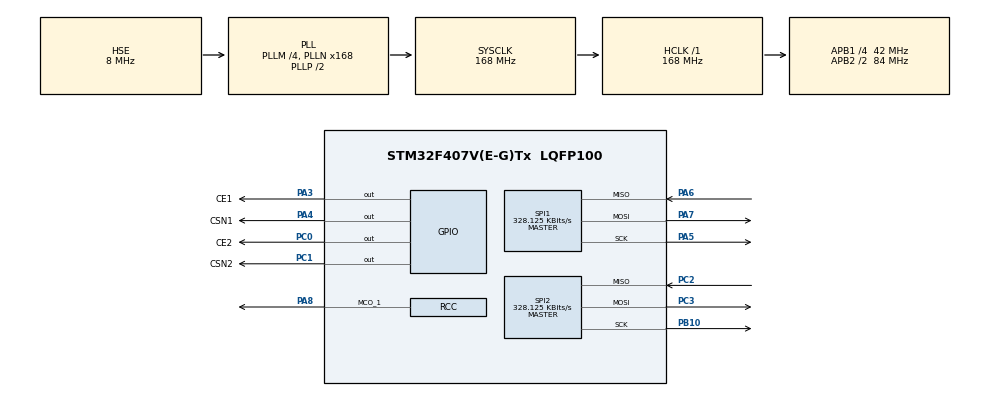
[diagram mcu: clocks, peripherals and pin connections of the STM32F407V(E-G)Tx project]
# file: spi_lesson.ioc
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Mcu.Family=STM32F4
Mcu.Name=STM32F407V(E-G)Tx
Mcu.Package=LQFP100
NVIC.PriorityGroup=NVIC_PRIORITYGROUP_4
PA13.Mode=Trace_Asynchronous_SW
PA13.Signal=SYS_JTMS-SWDIO
PA14.Mode=Trace_Asynchronous_SW
PA14.Signal=SYS_JTCK-SWCLK
PA3.GPIO_Label=CE1
PA3.Signal=GPIO_Output
PA4.GPIO_Label=CSN1
PA4.Signal=GPIO_Output
PA5.Mode=Full_Duplex_Master
PA5.Signal=SPI1_SCK
PA6.Mode=Full_Duplex_Master
PA6.Signal=SPI1_MISO
PA7.Mode=Full_Duplex_Master
PA7.Signal=SPI1_MOSI
PA8.Mode=Clock-out-1
PA8.Signal=RCC_MCO_1
PB10.Mode=Full_Duplex_Master
PB10.Signal=SPI2_SCK
PB3.Mode=Trace_Asynchronous_SW
PB3.Signal=SYS_JTDO-SWO
PC0.GPIO_Label=CE2
PC0.Signal=GPIO_Output
PC1.GPIO_Label=CSN2
PC1.Signal=GPIO_Output
PC2.Mode=Full_Duplex_Master
PC2.Signal=SPI2_MISO
PC3.Mode=Full_Duplex_Master
PC3.Signal=SPI2_MOSI
PH0-OSC_IN.Mode=HSE-External-Oscillator
PH0-OSC_IN.Signal=RCC_OSC_IN
PH1-OSC_OUT.Mode=HSE-External-Oscillator
PH1-OSC_OUT.Signal=RCC_OSC_OUT
ProjectManager.HeapSize=0x200
ProjectManager.StackSize=0x400
ProjectManager.TargetToolchain=TrueSTUDIO
RCC.48MHZClocksFreq_Value=84000000
RCC.AHBFreq_Value=168000000
RCC.APB1CLKDivider=RCC_HCLK_DIV4
RCC.APB1Freq_Value=42000000
RCC.APB1TimFreq_Value=84000000
RCC.APB2CLKDivider=RCC_HCLK_DIV2
RCC.APB2Freq_Value=84000000
RCC.APB2TimFreq_Value=168000000
RCC.CortexFreq_Value=168000000
RCC.HCLKFreq_Value=168000000
RCC.HSE_VALUE=8000000
RCC.HSI_VALUE=16000000
RCC.LSE_VALUE=32768
RCC.PLLM=4
RCC.PLLN=168
RCC.PLLSourceVirtual=RCC_PLLSOURCE_HSE
RCC.SYSCLKFreq_VALUE=168000000
RCC.SYSCLKSource=RCC_SYSCLKSOURCE_PLLCLK
RCC.VCOOutputFreq_Value=336000000
SPI1.BaudRatePrescaler=SPI_BAUDRATEPRESCALER_256
SPI1.CLKPhase=SPI_PHASE_1EDGE
SPI1.CLKPolarity=SPI_POLARITY_LOW
SPI1.CalculateBaudRate=328.125 KBits/s
SPI1.Direction=SPI_DIRECTION_2LINES
SPI1.Mode=SPI_MODE_MASTER
SPI1.VirtualType=VM_MASTER
SPI2.BaudRatePrescaler=SPI_BAUDRATEPRESCALER_128
SPI2.CalculateBaudRate=328.125 KBits/s
SPI2.Direction=SPI_DIRECTION_2LINES
SPI2.Mode=SPI_MODE_MASTER
SPI2.VirtualType=VM_MASTER
board=custom

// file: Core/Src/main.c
/* USER CODE BEGIN Header */
/**
 ******************************************************************************
 * @file           : main.c
 * @brief          : Main program body
 ******************************************************************************
 * @attention
 *
 * <h2><center>&copy; Copyright (c) 2019 STMicroelectronics.
 * All rights reserved.</center></h2>
 *
 * This software component is licensed by ST under BSD 3-Clause license,
 * the "License"; You may not use this file except in compliance with the
 * License. You may obtain a copy of the License at:
 *                        opensource.org/licenses/BSD-3-Clause
 *
 ******************************************************************************
 */
/* USER CODE END Header */

#include "main.h"

/* USER CODE BEGIN Includes */
#include "stdio.h"
#include "nrf.h"
/* USER CODE END Includes */

SPI_HandleTypeDef hspi1;
SPI_HandleTypeDef hspi2;

void SystemClock_Config(void);
static void MX_GPIO_Init(void);
static void MX_SPI1_Init(void);
static void MX_SPI2_Init(void);

int main(void)
{

	/* MCU Configuration--------------------------------------------------------*/

	/* Reset of all peripherals, Initializes the Flash interface and the Systick. */
	HAL_Init();

	/* Configure the system clock */
	SystemClock_Config();

	/* Initialize all configured peripherals */
	MX_GPIO_Init();
	MX_SPI1_Init();
	MX_SPI2_Init();
	/* USER CODE BEGIN 2 */
	init(nrf1);
	init(nrf2);
	/* USER CODE END 2 */
	/* Infinite loop */
	/* USER CODE BEGIN WHILE */
	while (1)
	{
		getFIFO_Status(nrf1);
		starTransmission(nrf1,19);
		/* USER CODE END WHILE */
	}
}

void SystemClock_Config(void)
{
	RCC_OscInitTypeDef RCC_OscInitStruct = {0};
	RCC_ClkInitTypeDef RCC_ClkInitStruct = {0};

	/** Configure the main internal regulator output voltage
	 */
	__HAL_RCC_PWR_CLK_ENABLE();
	__HAL_PWR_VOLTAGESCALING_CONFIG(PWR_REGULATOR_VOLTAGE_SCALE1);
	/** Initializes the CPU, AHB and APB busses clocks
	 */
	RCC_OscInitStruct.OscillatorType = RCC_OSCILLATORTYPE_HSI|RCC_OSCILLATORTYPE_HSE;
	RCC_OscInitStruct.HSEState = RCC_HSE_ON;
	RCC_OscInitStruct.HSIState = RCC_HSI_ON;
	RCC_OscInitStruct.HSICalibrationValue = RCC_HSICALIBRATION_DEFAULT;
	RCC_OscInitStruct.PLL.PLLState = RCC_PLL_ON;
	RCC_OscInitStruct.PLL.PLLSource = RCC_PLLSOURCE_HSE;
	RCC_OscInitStruct.PLL.PLLM = 4;
	RCC_OscInitStruct.PLL.PLLN = 168;
	RCC_OscInitStruct.PLL.PLLP = RCC_PLLP_DIV2;
	RCC_OscInitStruct.PLL.PLLQ = 4;
	if (HAL_RCC_OscConfig(&RCC_OscInitStruct) != HAL_OK)
	{
		Error_Handler();
	}
	/** Initializes the CPU, AHB and APB busses clocks
	 */
	RCC_ClkInitStruct.ClockType = RCC_CLOCKTYPE_HCLK|RCC_CLOCKTYPE_SYSCLK
			|RCC_CLOCKTYPE_PCLK1|RCC_CLOCKTYPE_PCLK2;
	RCC_ClkInitStruct.SYSCLKSource = RCC_SYSCLKSOURCE_PLLCLK;
	RCC_ClkInitStruct.AHBCLKDivider = RCC_SYSCLK_DIV1;
	RCC_ClkInitStruct.APB1CLKDivider = RCC_HCLK_DIV4;
	RCC_ClkInitStruct.APB2CLKDivider = RCC_HCLK_DIV2;

	if (HAL_RCC_ClockConfig(&RCC_ClkInitStruct, FLASH_LATENCY_5) != HAL_OK)
	{
		Error_Handler();
	}
	HAL_RCC_MCOConfig(RCC_MCO1, RCC_MCO1SOURCE_HSI, RCC_MCODIV_1);
}

static void MX_SPI1_Init(void)
{

	/* SPI1 parameter configuration*/
	hspi1.Instance = SPI1;
	hspi1.Init.Mode = SPI_MODE_MASTER;
	hspi1.Init.Direction = SPI_DIRECTION_2LINES;
	hspi1.Init.DataSize = SPI_DATASIZE_8BIT;
	hspi1.Init.CLKPolarity = SPI_POLARITY_LOW;
	hspi1.Init.CLKPhase = SPI_PHASE_1EDGE;
	hspi1.Init.NSS = SPI_NSS_SOFT;
	hspi1.Init.BaudRatePrescaler = SPI_BAUDRATEPRESCALER_256;
	hspi1.Init.FirstBit = SPI_FIRSTBIT_MSB;
	hspi1.Init.TIMode = SPI_TIMODE_DISABLE;
	hspi1.Init.CRCCalculation = SPI_CRCCALCULATION_DISABLE;
	hspi1.Init.CRCPolynomial = 10;
	if (HAL_SPI_Init(&hspi1) != HAL_OK)
	{
		Error_Handler();
	}

}

static void MX_SPI2_Init(void)
{

	/* SPI2 parameter configuration*/
	hspi2.Instance = SPI2;
	hspi2.Init.Mode = SPI_MODE_MASTER;
	hspi2.Init.Direction = SPI_DIRECTION_2LINES;
	hspi2.Init.DataSize = SPI_DATASIZE_8BIT;
	hspi2.Init.CLKPolarity = SPI_POLARITY_LOW;
	hspi2.Init.CLKPhase = SPI_PHASE_1EDGE;
	hspi2.Init.NSS = SPI_NSS_SOFT;
	hspi2.Init.BaudRatePrescaler = SPI_BAUDRATEPRESCALER_128;
	hspi2.Init.FirstBit = SPI_FIRSTBIT_MSB;
	hspi2.Init.TIMode = SPI_TIMODE_DISABLE;
	hspi2.Init.CRCCalculation = SPI_CRCCALCULATION_DISABLE;
	hspi2.Init.CRCPolynomial = 10;
	if (HAL_SPI_Init(&hspi2) != HAL_OK)
	{
		Error_Handler();
	}

}

static void MX_GPIO_Init(void)
{
	GPIO_InitTypeDef GPIO_InitStruct = {0};

	/* GPIO Ports Clock Enable */
	__HAL_RCC_GPIOH_CLK_ENABLE();
	__HAL_RCC_GPIOC_CLK_ENABLE();
	__HAL_RCC_GPIOA_CLK_ENABLE();
	__HAL_RCC_GPIOB_CLK_ENABLE();

	/*Configure GPIO pin Output Level */
	HAL_GPIO_WritePin(GPIOC, CE2_Pin|CSN2_Pin, GPIO_PIN_RESET);

	/*Configure GPIO pin Output Level */
	HAL_GPIO_WritePin(GPIOA, CE1_Pin|CSN1_Pin, GPIO_PIN_RESET);

	/*Configure GPIO pins : CE2_Pin CSN2_Pin */
	GPIO_InitStruct.Pin = CE2_Pin|CSN2_Pin;
	GPIO_InitStruct.Mode = GPIO_MODE_OUTPUT_PP;
	GPIO_InitStruct.Pull = GPIO_NOPULL;
	GPIO_InitStruct.Speed = GPIO_SPEED_FREQ_LOW;
	HAL_GPIO_Init(GPIOC, &GPIO_InitStruct);

	/*Configure GPIO pins : CE1_Pin CSN1_Pin */
	GPIO_InitStruct.Pin = CE1_Pin|CSN1_Pin;
	GPIO_InitStruct.Mode = GPIO_MODE_OUTPUT_PP;
	GPIO_InitStruct.Pull = GPIO_NOPULL;
	GPIO_InitStruct.Speed = GPIO_SPEED_FREQ_LOW;
	HAL_GPIO_Init(GPIOA, &GPIO_InitStruct);

	/*Configure GPIO pin : PA8 */
	GPIO_InitStruct.Pin = GPIO_PIN_8;
	GPIO_InitStruct.Mode = GPIO_MODE_AF_PP;
	GPIO_InitStruct.Pull = GPIO_NOPULL;
	GPIO_InitStruct.Speed = GPIO_SPEED_FREQ_LOW;
	GPIO_InitStruct.Alternate = GPIO_AF0_MCO;
	HAL_GPIO_Init(GPIOA, &GPIO_InitStruct);

}

void Error_Handler(void)
{
}

/************************ (C) COPYRIGHT STMicroelectronics *****END OF FILE****/
